# iND83216 register map
Vendor: Indiemicro; Series: RealplumTiny; File version: 1.00
CPU: CM0 r0p1, selectable endian, no MPU, no FPU, 4 interrupt priority bits
Registers are 32-bit, read-write, no defined reset value unless marked. A register's access mark holds for its fields unless they carry their own. Offsets are from the block's base; [hi:lo] are bit positions.

## TRIMHV — Trim bits & Control bits in 5V power domain
Base 0x50000900; register names take the prefix TRIMHV_
0x00 RETAIN0 — Retained data 0
  [15:0] RETAIN0 — Firmware scratch register 0. Only reset at power-on (e.g contents retained in Hibernate mode and retained despite any hard or soft resets)
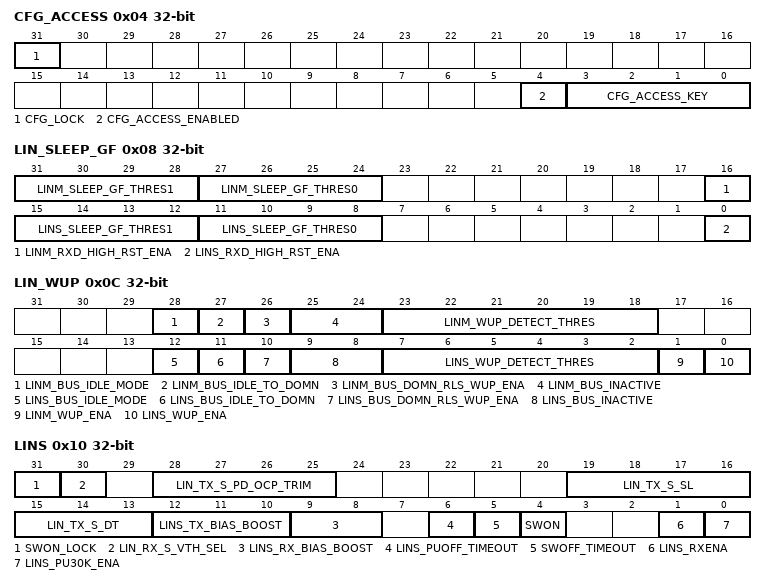
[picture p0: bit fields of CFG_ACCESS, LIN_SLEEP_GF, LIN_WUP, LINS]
0x04 CFG_ACCESS — 5V domain's configuration regs access
  [31] CFG_LOCK — Set Only bit. Write 1 to this bit to lock CFG_CODE bits.
  [4] CFG_ACCESS_ENABLED ro — A status flag that is set when 5V domain's configuration regs access is enabled
  [3:0] CFG_ACCESS_KEY — Write the value 0xB to this register to enable 'trim access' (which allows write access to various trim settings and production test options). Write any other value to disable trim access.
0x08 LIN_SLEEP_GF — LINS Glitch Filter Configuration in active mode. NOTE:The write operation of this field register takes effect by configuring 'TRIM_HV->CFG.CFG_ACCESS_KEY = 0xB'
  [31:28] LINM_SLEEP_GF_THRES1 — LINM RXD glitch filter threshold for 0 to 1, detect '1' width of (T_clk_lf*resetvalue = 4us*3 = 12[us]
  [27:24] LINM_SLEEP_GF_THRES0 — LINM RXD glitch filter threshold for 1 to 0, detect '0' width of (T_clk_lf*resetvalue = 4us*3 = 12[us]
  [16] LINM_RXD_HIGH_RST_ENA — Enable signal that LINs RXD glitch filter at sleep mode is asynchronous reset by high of LINs_RXD. If set, LINM_WUP_DETECT_THRES should be set less than 150us-4us*(LINM_SLEEP_GF_THRES0+5)
  [15:12] LINS_SLEEP_GF_THRES1 — LINS RXD glitch filter threshold for 0 to 1, detect '1' width of (T_clk_lf*resetvalue = 4us*3 = 12[us]
  [11:8] LINS_SLEEP_GF_THRES0 — LINS RXD glitch filter threshold for 1 to 0, detect '0' width of (T_clk_lf*resetvalue = 4us*3 = 12[us]
  [0] LINS_RXD_HIGH_RST_ENA — Enable signal that LINs RXD glitch filter at sleep mode is asynchronous reset by high of LINs_RXD. If set, LINS_WUP_DETECT_THRES should be set less than 150us-4us*(LINS_SLEEP_GF_THRES0+5)
0x0C LIN_WUP — LIN Wakeup Control, NOTE:The write operation of this field register takes effect by configuring 'TRIM_HV->CFG.CFG_ACCESS_KEY = 0xB'
  [28] LINM_BUS_IDLE_MODE — LIN Master Bus Dominant Enable Mode. 0x0: Enabled when RXD is LOW0x1: Always On
  [27] LINM_BUS_IDLE_TO_DOMN ro — Dominant Bus Idle Timeout. The bit is set by the lin core if LIN is in hardware mode & the bus is stuck at dominant inactivity state for 4s~10s. Any bus transition will clear this bit. LIN Master's pullup will be disabled when it is set.
  [26] LINM_BUS_DOMN_RLS_WUP_ENA — LIN Master Bus Dominant Release Wakeup Enable. Set to trigger lin wakeup if bus dominant condition is released after BUS_IDLE_TIMEOUT_DOMINANT is detected.
  [25:24] LINM_BUS_INACTIVE — LIN Master Bus Inactivity Time.
  [23:18] LINM_WUP_DETECT_THRES — LIN Master Wakeup Detection Threshold. Threshold setting(LF_CLK_PREDIV clock cycls) of lin wakeup signal. For instace, if target threshold is 150us@LF_CLK_PREDIV=250KHz, WUP_DETECT_THRES = 150/(1000/250)-1.
  [12] LINS_BUS_IDLE_MODE — LIN Slave Bus Dominant Enable Mode. 0x0: Enabled when RXD is LOW0x1: Always On
  [11] LINS_BUS_IDLE_TO_DOMN ro — Dominant Bus Idle Timeout. The bit is set by the lin core if LIN is in hardware mode & the bus is stuck at dominant inactivity state for 4s~10s. Any bus transition will clear this bit. LIN Slave's pullup will be disabled when it is set.
  [10] LINS_BUS_DOMN_RLS_WUP_ENA — LIN Slave Bus Dominant Release Wakeup Enable. Set to trigger lin wakeup if bus dominant condition is released after BUS_IDLE_TIMEOUT_DOMINANT is detected.
  [9:8] LINS_BUS_INACTIVE — LIN Slave Bus Inactivity Time.
  [7:2] LINS_WUP_DETECT_THRES — LIN Slave Wakeup Detection Threshold. Threshold setting(LF_CLK_PREDIV clock cycls) of lin wakeup signal. For instace, if target threshold is 150us@LF_CLK_PREDIV=250KHz, WUP_DETECT_THRES = 150/(1000/250)-1.
  [1] LINM_WUP_ENA — LIN Master Wakeup Enable. it enables the detect of a wakeup signal on the LIN_OUT bus
  [0] LINS_WUP_ENA — LIN Slave Wakeup Enable. it enables the detect of a wakeup signal on the LIN_IN bus
0x10 LINS — LIN slave Pin Control. NOTE:The write operation of this field register takes effect by configuring 'TRIM_HV->CFG.CFG_ACCESS_KEY = 0xB'
  [31] SWON_LOCK — SWON Lock Bit.
  [30] LIN_RX_S_VTH_SEL — sel RX Comparator reference voltage, 0: VBAT/12, 1: VBAT/24
  [28:25] LIN_TX_S_PD_OCP_TRIM — When vbat=13V, the Vbus voltage trigger OCP0x0: 15 V0x4: 16 V0x8: 16.5V0xf: 17.5V
  [19:16] LIN_TX_S_SL — LIN Slave TX driver slew rate select. Slew from 40%*Vbat to 60%*Vbat @Vbat=13V,Cbus=1nF. 0000 -> 1110: 1.28V/us ~ 2.29V/us, step is about 0.3V/us 1111: about 10V/us for fast LIN mode
  [15:13] LIN_TX_S_DT — LIN Slave duty cycle adjust. 0x0: duty cycle = 0.4860x1: duty cycle = 0.4860x2: duty cycle = 0.4930x3: duty cycle = 0.5010x4: duty cycle = 0.5110x5: duty cycle = 0.52 0x6: duty cycle = 0.5270x7: duty cycle = 0.537
  [12:10] LINS_TX_BIAS_BOOST — LIN Slave IO TX Bias select. boost LIN Slave TX driver current. should within 40mA ~ 200mA0x0: 44.8 mA0x1: 56.6 mA0x2: 67.8 mA0x3: 78.5 mA0x4: 88.7 mA0x5: 98.6 mA0x6: 108.3 mA0x7: 117.5 mA
  [9:8] LINS_RX_BIAS_BOOST — adjust rise delay from LIN_IN to Input of LINS Controller.0x0: 1.649 us0x1: 0.960 us0x2: 0.699 us0x3: 0.547 us
  [6] LINS_PUOFF_TIMEOUT — LINS Pullup Disable in dominant TimeOut condition. Set to disable LINS 30K pullup in case that lin bus is shorted to ground(Bus idle dominant timeout is detected) for saving power. LINS Pullup will be recovered automatically if bus idle dominant timeout is released by any bus activity. Only reset by power-on sequence.
  [5] SWOFF_TIMEOUT — Switch off in dominant TimeOut condition. Set to disconnect lin switch in case that lin bus is shorted to ground(Bus idle dominant timeout is detected) for saving power. LIN Switch will be recovered automatically if bus idle dominant timeout is released by any bus activity. Only reset by power-on sequence.
  [4] SWON — LIN Dual Mode Switch On. Set to enable dual-mode lin switch. Only reset by power-on sequence. This bit can be locked by setting SWON_LOCK.
  [1] LINS_RXENA — LIN receive enable.
  [0] LINS_PU30K_ENA — LIN 30K pullup enable.
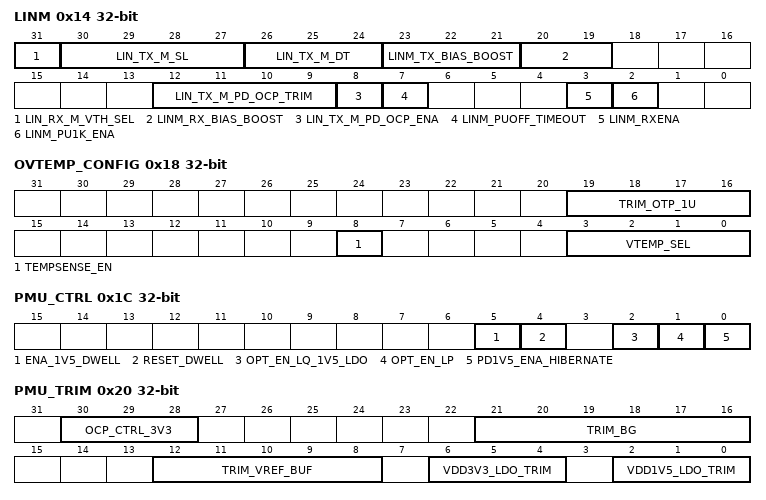
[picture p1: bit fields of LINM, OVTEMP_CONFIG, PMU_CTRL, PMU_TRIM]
0x14 LINM — LIN Master Pin Control. NOTE:The write operation of this field register takes effect by configuring 'TRIM_HV->CFG.CFG_ACCESS_KEY = 0xB'
  [31] LIN_RX_M_VTH_SEL — sel RX Comparator reference voltage, 0: VBAT/12, 1: VBAT/24
  [30:27] LIN_TX_M_SL — LIN Master TX driver slew rate select. Slew from 40%*Vbat to 60%*Vbat @Vbat=13V,Cbus=1nF. 0000 -> 1110: 1.28V/us ~ 2.29V/us, step is about 0.3V/us 1111: about 10V/us for fast LIN mode
  [26:24] LIN_TX_M_DT — LIN Master duty cycle adjust. 0x0: duty cycle = 0.4860x1: duty cycle = 0.4860x2: duty cycle = 0.4930x3: duty cycle = 0.5010x4: duty cycle = 0.5110x5: duty cycle = 0.52 0x6: duty cycle = 0.5270x7: duty cycle = 0.537
  [23:21] LINM_TX_BIAS_BOOST — LIN Master IO TX Bias select. boost LIN Master TX driver current, should within 40mA ~ 200mA0x0: 44.8 mA0x1: 56.6 mA0x2: 67.8 mA0x3: 78.5 mA0x4: 88.7 mA0x5: 98.6 mA0x6: 108.3 mA0x7: 117.5 mA
  [20:19] LINM_RX_BIAS_BOOST — adjust rise delay from LIN_OUT to Input of LINM Controller.0x0: 1.649 us0x1: 0.960 us0x2: 0.699 us0x3: 0.547 us
  [12:9] LIN_TX_M_PD_OCP_TRIM — When vbat=13V, the Vbus voltage trigger OCP0x0: 15 V0x4: 16 V0x8: 16.5V0xf: 17.5V
  [8] LIN_TX_M_PD_OCP_ENA — Enable lin tx master pulldn over current protect to solve the lin bus slew rate emi issue
  [7] LINM_PUOFF_TIMEOUT — LINM 1K Pullup disable in dominant TimeOut condition. Set to disable LINM 1K pullup in case that lin bus is shorted to ground(Bus idle dominant timeout is detected) for saving power. LINS 1K Pullup will be recovered automatically if bus idle dominant timeout is released by any bus activity. If this bit is set & SWON = 1, LINM's 30K pullup will be enabled for preventing bus floating. Only reset by power-on sequence.
  [3] LINM_RXENA — LIN receive enable.
  [2] LINM_PU1K_ENA — LIN 1K pullup enable.
0x18 OVTEMP_CONFIG — OVTEMP configuration. NOTE:The write operation of this field register takes effect by configuring 'TRIM_HV->CFG.CFG_ACCESS_KEY = 0xB'
  [19:16] TRIM_OTP_1U — Trim 1uA for OTP @27C0x0: 0uA 0x1: 0.125uA 0x2: 0.25 uA 0x3: 0.375uA 0x4: 0.5uA 0x5: 0.625uA 0x6: 0.75uA 0x7: 0.875uA 0x8: 1uA (default)0x9: 1.125uA 0xa: 1.25uA 0xb: 1.375uA 0xc: 1.5uA 0xd: 1.625uA 0xe: 1.75uA 0xf: 1.875uA
  [8] TEMPSENSE_EN — enable Temp Sensor Analog Part. Set to enable Temperature Sensor analog circuit.
  [3:0] VTEMP_SEL — Over Temp protect threshold temp trim. Select the OVTEMP threshold level for the monitor.0x0: Rising: 123.4; Falling: 107.4 ; HYS: 160x1: Rising: 127.4; Falling: 110.4 ; HYS: 170x2: Rising: 131.4; Falling: 114.4 ; HYS: 170x3: Rising: 135.4; Falling: 117.4 ; HYS: 180x4: Rising: 138.4; Falling: 121.4 ; HYS: 170x5: Rising: 142.4; Falling: 125.4 ; HYS: 170x6: Rising: 146.4; Falling: 128.4 ; HYS: 180x7: Rising: 151.4; Falling: 132.4 ; HYS: 190x8: Rising: 155.4; Falling: 136.4 ; HYS: 190x9: Rising: 165.0; Falling: 132.0 ; HYS: 330xa: Rising: 163.4; Falling: 144.4 ; HYS: 190xb: Rising: 167.4; Falling: 148.4 ; HYS: 190xc: Rising: 171.4; Falling: 153.4 ; HYS: 180xd: Rising: 175.4; Falling: 157.4 ; HYS: 180xe: Rising: 180.4; Falling: 161.4 ; HYS: 190xf: Rising: 184.4; Falling: 166.4 ; HYS: 18
0x1C PMU_CTRL — PMU Control. NOTE:The write operation of this field register takes effect by configuring 'TRIM_HV->CFG.CFG_ACCESS_KEY = 0xB'
  [5] ENA_1V5_DWELL — ENA_1V5 dwell time. Defines the amount of time spent in the 'ENA_1V5' state.
  [4] RESET_DWELL — Reset dwell time. Defines the amount of time spent in the 'RESET' state.
  [2] OPT_EN_LQ_1V5_LDO — Capless 1.5V ldo low power mode, set 1 to enter low power at Deepsleep mode.
  [1] OPT_EN_LP — Set to enable of low power mode for BG_TOP at Deepsleep Mode.
  [0] PD1V5_ENA_HIBERNATE — enable of 1V5 Power Domain at Hibernate mode. set to enable the 1V5 Power Domain at Hibernate mode, this mode is defined as DEEPSLEEP mode.
0x20 PMU_TRIM — PMU Trim Register. NOTE:The write operation of this field register takes effect by configuring 'TRIM_HV->CFG.CFG_ACCESS_KEY = 0xB'
  [30:28] OCP_CTRL_3V3 — OCP trim for 3V3 LDO(default 26.4mA). 0x0: 19.0 mA0x1: 21.4 mA0x2: 24.0 mA0x3: 26.4 mA(default)0x4: 28.7 mA0x5: 31.2 mA0x6: 33.7 mA0x7: 36.0 mA
  [21:16] TRIM_BG — Trim the BG core output voltage
  [12:8] TRIM_VREF_BUF — Trim the buffer refernce voltage include VREF_1/VREF_1P1/VREF_0P75/VREF_0P6.
  [6:4] VDD3V3_LDO_TRIM — 3.3V LDO output trim. at PMU debug mode0x0: 3.079V0x1: 3.138V0x2: 3.199V0x3: 3.264V0x4: 3.333V(default)0x5: 3.405V0x6: 3.482V0x7: 3.563V
  [2:0] VDD1V5_LDO_TRIM — 1.5V LDO Capless output trim. at PMU debug mode0x0: 1.454 V0x1: 1.481 V0x2: 1.511 V0x3: 1.546 V(default)0x4: 1.574 V0x5: 1.606 V0x6: 1.642 V0x7: 1.682 V
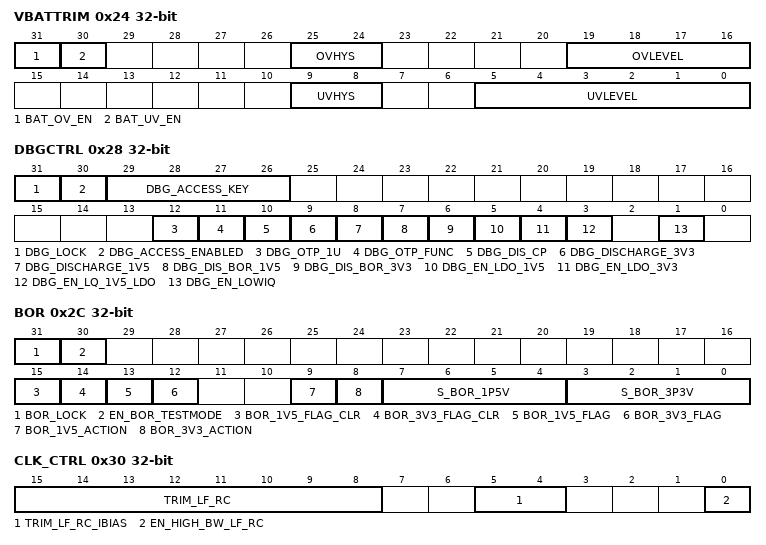
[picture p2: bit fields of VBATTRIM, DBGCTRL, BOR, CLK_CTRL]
0x24 VBATTRIM — VBAT Monitor Trim Register. NOTE:The write operation of this field register takes effect by configuring 'TRIM_HV->CFG.CFG_ACCESS_KEY = 0xB'
  [31] BAT_OV_EN — Battery Over Voltage Monitor Enable. Set to enable the vbat over voltage monitor analog comparator circuit.
  [30] BAT_UV_EN — Battery Under Voltage Monitor Enable. Set to enable the vbat under voltage monitor analog comparator circuit.
  [25:24] OVHYS — Battery Voltage Monitor Over Voltage Hysterisis Select. Selects the hysterisis level for the Over Voltage monitor.0x0: 0.46V0x1: 1.16V0x2: 1.81V0x3: 2.41V
  [19:16] OVLEVEL — Battery Voltage Monitor Over Voltage Select. Selects the reference level for the Over Voltage monitor to output one-hot Configuration to Analog Module.(The following table is base on HYS_TRIM_OV is set '0', for more detail, please contact the IP owner)0x0: Vrise:14.42, Vfall:14.07 Hys:350m0x1: Vrise:14.88, Vfall:14.53 Hys:350m0x2: Vrise:15.38, Vfall:15.01 Hys:370m0x3: Vrise:15.91, Vfall:15.53 Hys:380m0x4: Vrise:16.48, Vfall:16.08 Hys:400m0x5: Vrise:17.09, Vfall:16.68 Hys:410m0x6: Vrise:17.74, Vfall:17.32 Hys:420m0x7: Vrise:18.45, Vfall:18.01 Hys:440m0x8: Vrise:19.22, Vfall:18.76 Hys:460m0x9: Vrise:20.06, Vfall:19.58 Hys:480m0xa: Vrise:20.97, Vfall:20.47 Hys:500m0xb: Vrise:21.97, Vfall:21.44 Hys:530m0xc: Vrise:23.07, Vfall:22.52 Hys:550m0xd: Vrise:24.28, Vfall:23.70 Hys:580m0xe: Vrise:25.63, Vfall:25.02 Hys:610m0xf: Vrise:27.14, Vfall:26.49 Hys:650m
  [9:8] UVHYS — Battery Voltage Monitor Under Voltage Hysterisis Select. Selects the hysterisis level for the Under Voltage monitor.0x0: 0.20V0x1: 0.29V0x2: 0.38V0x3: 0.47V
  [5:0] UVLEVEL — Battery Voltage Monitor Under Voltage Select. Selects the reference level for the Under Voltage monitor. If UVLEVEL[5:3]>0x04, the actual analog trim value is the same as UVLEVEL=0x0A. The UVLEVEL threshold is mononically increased with the setting.(The following table is base on HYS_TRIM_UV is set '1', for more detail, please contact the IP owner)0x0: Vrise: 4.866 Vfall: 4.626 , Hys: 240m 0x1: Vrise: 4.936 Vfall: 4.696 , Hys: 240m 0x2: Vrise: 5.016 Vfall: 4.766 , Hys: 250m 0x3: Vrise: 5.086 Vfall: 4.836 , Hys: 250m 0x4: Vrise: 5.166 Vfall: 4.916 , Hys: 250m 0x5: Vrise: 5.256 Vfall: 4.986 , Hys: 270m 0x6: Vrise: 5.336 Vfall: 5.066 , Hys: 270m 0x7: Vrise: 5.426 Vfall: 5.146 , Hys: 280m 0x8: Vrise: 5.516 Vfall: 5.236 , Hys: 280m 0x9: Vrise: 5.606 Vfall: 5.326 , Hys: 280m 0xa: Vrise: 5.706 Vfall: 5.416 , Hys: 290m 0xb: Vrise: 5.806 Vfall: 5.506 , Hys: 300m 0xc: Vrise: 5.906 Vfall: 5.606 , Hys: 300m 0xd: Vrise: 6.016 Vfall: 5.706 , Hys: 310m 0xe: Vrise: 6.126 Vfall: 5.806 , Hys: 320m 0xf: Vrise: 6.246 Vfall: 5.916 , Hys: 330m 0x10: Vrise: 6.366 Vfall: 6.026 , Hys: 340m 0x11: Vrise: 6.486 Vfall: 6.136 , Hys: 350m 0x12: Vrise: 6.616 Vfall: 6.256 , Hys: 360m 0x13: Vrise: 6.756 Vfall: 6.386 , Hys: 370m 0x14: Vrise: 6.896 Vfall: 6.516 , Hys: 380m 0x15: Vrise: 7.036 Vfall: 6.656 , Hys: 380m 0x16: Vrise: 7.196 Vfall: 6.796 , Hys: 400m 0x17: Vrise: 7.356 Vfall: 6.946 , Hys: 410m 0x18: Vrise: 7.516 Vfall: 7.096 , Hys: 420m 0x19: Vrise: 7.696 Vfall: 7.256 , Hys: 440m 0x1a: Vrise: 7.876 Vfall: 7.426 , Hys: 450m 0x1b: Vrise: 8.066 Vfall: 7.606 , Hys: 460m 0x1c: Vrise: 8.266 Vfall: 7.786 , Hys: 480m 0x1d: Vrise: 8.486 Vfall: 7.986 , Hys: 500m 0x1e: Vrise: 8.706 Vfall: 8.186 , Hys: 520m 0x1f: Vrise: 8.946 Vfall: 8.406 , Hys: 540m 0x20: Vrise: 9.186 Vfall: 8.626 , Hys: 560m 0x21: Vrise: 9.456 Vfall: 8.866 , Hys: 590m 0x22: Vrise: 9.726 Vfall: 9.126 , Hys: 500m 0x23: Vrise: 10.03 Vfall: 9.386 , Hys: 640m 0x24: Vrise: 10.34 Vfall: 9.676 , Hys: 660m 0x25: Vrise: 10.68 Vfall: 9.976 , Hys: 700m 0x26: Vrise: 11.03 Vfall: 10.3 , Hys: 730m 0x27: Vrise: 11.41 Vfall: 10.65 , Hys: 760m
0x28 DBGCTRL — PMU Debug Control. NOTE:The write operation of this field register takes effect by configuring 'TRIM_HV->CFG.CFG_ACCESS_KEY = 0xB'
  [31] DBG_LOCK — Set Only bit. Set this bit to lock DBG_CODE bits.
  [30] DBG_ACCESS_ENABLED ro — A status flag that is set when debug access is enabled
  [29:26] DBG_ACCESS_KEY — Write the value 0x5 to this register to enable debug options. Write any other value to disable the debug options.
  [12] DBG_OTP_1U — En test 1uA BIAS for OTP, need trim the BIAS setting time 64us
  [11] DBG_OTP_FUNC — When set 1, OTP value is set to 140C. In ATE 150C Test, read the ovtemp flag to verify function
  [10] DBG_DIS_CP — Set 1, Shut down PRE5V ChargePump, PRE5V=Vzener-Vgs. Only take effect at Debug mode(DBG_TEST = 1) at PMU debug mode
  [9] DBG_DISCHARGE_3V3 — 3V3 LDO Debug Mode: a. Set '0' to test 3V3-LDO function; b. Set '1' to test 3V3-LDO Discharge Circuit.
  [8] DBG_DISCHARGE_1V5 — 1V5 LDO Debug Mode: a. Set '0' to test 1V5-LDO function; b. Set '1' to test 1V5-LDO Discharge Circuit.
  [7] DBG_DIS_BOR_1V5 — Debug Contrl of dis_bor_1v5 at PMU debug mode
  [6] DBG_DIS_BOR_3V3 — Debug Contrl of dis_bor_3v3 at PMU debug mode
  [5] DBG_EN_LDO_1V5 — Debug Contrl of en_ldo_1v5 at PMU debug mode.
  [4] DBG_EN_LDO_3V3 — NOTE:Don't use.Debug Contrl of en_ldo_3v3 at PMU debug mode
  [3] DBG_EN_LQ_1V5_LDO — 1.5V ldo low power mode, set 1 to enter low power at PMU debug mode
  [1] DBG_EN_LOWIQ — Set to enable of low power mode for BG_TOP at PMU debug mode
0x2C BOR — BOR configuration
  [31] BOR_LOCK — Set Only bit. Set this bit to lock BOR_ACTION & S_BOR bits.
  [30] EN_BOR_TESTMODE — BOR Testmode Enable. 0x0: BOR Testmode Disabled: Reference Voltage for BOR is from Band Gap (Functional Mode)0x1: BOR Testmode Enabled: Reference Voltage for BOR is from gpio1_anaOut (Test Mode
  [15] BOR_1V5_FLAG_CLR wo — BOR 1v5 clear. Set to clear the 1.5V brownout detected flag
  [14] BOR_3V3_FLAG_CLR wo — BOR 3v3 clear. Set to clear the 3.3V brownout detected flag
  [13] BOR_1V5_FLAG ro — BOR 1v5 flag. Set by the hardware when a brownout of the 1.5V supply is detected.
  [12] BOR_3V3_FLAG ro — BOR 3v3 flag. Set by the hardware when a brownout of the 3.3V supply is detected.
  [9] BOR_1V5_ACTION — BOR 1v5 action. Defines the consequences of brown-out condition on the 1v5 supply being detected by the hardware. NOTE: The write operation will be locked by BOR_SFRS->BOR_LOCK0x1: IRQ generated0x0: Hard reset generated
  [8] BOR_3V3_ACTION — BOR 3v3 action. Defines the consequences of brown-out condition on the 3v3 supply being detected by the hardware. NOTE: The write operation will be locked by BOR_SFRS->BOR_LOCK0x1: IRQ generated0x0: Hard reset generated
  [7:4] S_BOR_1P5V — BOR 1v5 threshold. Select the BOR threshold voltage level for the 1v5 regulator. Following typical value can be used as reference: NOTE: The write operation will be locked by BOR_SFRS->BOR_LOCK0x0: Vr: 1.111 V, Vf: 1.076 V, HYS:35m0x1: Vr: 1.136 V, Vf: 1.096 V, HYS:40m0x2: Vr: 1.161 V, Vf: 1.121 V, HYS:40m0x3: Vr: 1.186 V, Vf: 1.146 V, HYS:40m0x4: Vr: 1.216 V, Vf: 1.176 V, HYS:40m0x5: Vr: 1.246 V, Vf: 1.201 V, HYS:45m0x6: Vr: 1.276 V, Vf: 1.231 V, HYS:45m0x7: Vr: 1.306 V, Vf: 1.261 V, HYS:45m(Default)0x8: Vr: 1.341 V, Vf: 1.296 V, HYS:45m0x9: Vr: 1.376 V, Vf: 1.331 V, HYS:45m0xa: Vr: 1.411 V, Vf: 1.366 V, HYS:45m0xb: Vr: 1.451 V, Vf: 1.401 V, HYS:50m0xc: Vr: 1.496 V, Vf: 1.441 V, HYS:55m0xd: Vr: 1.536 V, Vf: 1.486 V, HYS:50m0xe: Vr: 1.586 V, Vf: 1.531 V, HYS:55m0xf: Vr: 1.636 V, Vf: 1.581 V, HYS:55m
  [3:0] S_BOR_3P3V — BOR 3v3 threshold. Select the BOR threshold voltage level for the 3v3 regulator, Following typical value can be used as reference: NOTE: The write operation will be locked by BOR_SFRS->BOR_LOCK0x0: Vr: 2.481 V, Vf: 2.401 V, HYS:80m 0x1: Vr: 2.546 V, Vf: 2.461 V, HYS:85m 0x2: Vr: 2.606 V, Vf: 2.521 V, HYS:85m 0x3: Vr: 2.676 V, Vf: 2.586 V, HYS:90m 0x4: Vr: 2.746 V, Vf: 2.656 V, HYS:90m 0x5: Vr: 2.821 V, Vf: 2.726 V, HYS:95m 0x6: Vr: 2.896 V, Vf: 2.801 V, HYS:95m 0x7: Vr: 2.981 V, Vf: 2.881 V, HYS:100m(Default)0x8: Vr: 3.066 V, Vf: 2.966 V, HYS:100m0x9: Vr: 3.161 V, Vf: 3.056 V, HYS:105m0xa: Vr: 3.261 V, Vf: 3.151 V, HYS:110m0xb: Vr: 3.366 V, Vf: 3.251 V, HYS:115m0xc: Vr: 3.476 V, Vf: 3.361 V, HYS:115m0xd: Vr: 3.596 V, Vf: 3.476 V, HYS:120m0xe: Vr: 3.726 V, Vf: 3.601 V, HYS:125m0xf: Vr: 3.861 V, Vf: 3.736 V, HYS:125m
0x30 CLK_CTRL — Clock controls for 5V(always on) domain. NOTE:The write operation of this field register takes effect by configuring 'TRIM_HV->CFG.CFG_ACCESS_KEY = 0xB'
  [15:8] TRIM_LF_RC — LF RC oscillator trim. Following value only used as a reference:(the trim freq is non-linear) 0x0: freq(250k)=126.4Khz0xa8: freq(250k)=250.0Khz0xac: freq(250k)=256.0Khz0xff: freq(250k)=519.7Khz
  [5:4] TRIM_LF_RC_IBIAS — LF RC oscillator bias current trim. trim rc250k bias current) 0x0: 130nA0x1: 158nA0x2: 200nA0x3: 265nA
  [0] EN_HIGH_BW_LF_RC — set to enable to increase internal comparator bandwidth
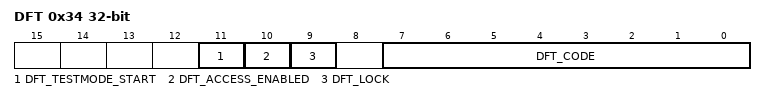
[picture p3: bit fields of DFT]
0x34 DFT
  [11] DFT_TESTMODE_START wo — Puts the ASIC into DFT testmode. Once the start bit is set, the I/O configuration will switch from Application mode to DFT Test Mode. The General Purpose I/Os will be configured as a JTAG interface. Once Test Mode is enabled, the ASIC will be boundary terminated and the processor will lose the ability to communicate with any ASIC peripherals. A chip power cycle is required to get out of the DFT test mode. Test Mode Enable state.
  [10] DFT_ACCESS_ENABLED ro — A status flag that is set when DFT_TESTMODE_START access is enabled.
  [9] DFT_LOCK — Set Only bit. Write 1 to this bit to lock DFT testmode and DFT_CODE register.
  [7:0] DFT_CODE wo — Write the value 0x1C to this register to Unlock DFT_TESTMODE_START register.
